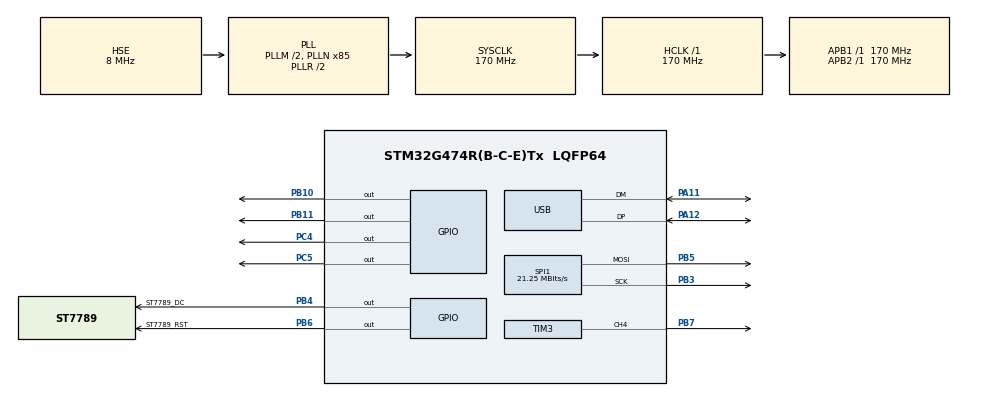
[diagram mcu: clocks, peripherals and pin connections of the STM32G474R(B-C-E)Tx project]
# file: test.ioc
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Dma.Request0=TIM3_CH4
Dma.TIM3_CH4.0.Direction=DMA_PERIPH_TO_MEMORY
Dma.TIM3_CH4.0.EventEnable=DISABLE
Dma.TIM3_CH4.0.Instance=DMA1_Channel1
Dma.TIM3_CH4.0.MemDataAlignment=DMA_MDATAALIGN_HALFWORD
Dma.TIM3_CH4.0.MemInc=DMA_MINC_ENABLE
Dma.TIM3_CH4.0.Mode=DMA_NORMAL
Dma.TIM3_CH4.0.PeriphDataAlignment=DMA_PDATAALIGN_HALFWORD
Dma.TIM3_CH4.0.PeriphInc=DMA_PINC_DISABLE
Dma.TIM3_CH4.0.Polarity=HAL_DMAMUX_REQ_GEN_RISING
Dma.TIM3_CH4.0.Priority=DMA_PRIORITY_LOW
Dma.TIM3_CH4.0.RequestNumber=1
Dma.TIM3_CH4.0.SignalID=NONE
Dma.TIM3_CH4.0.SyncEnable=DISABLE
Dma.TIM3_CH4.0.SyncPolarity=HAL_DMAMUX_SYNC_NO_EVENT
Dma.TIM3_CH4.0.SyncRequestNumber=1
Dma.TIM3_CH4.0.SyncSignalID=NONE
Mcu.Family=STM32G4
Mcu.Name=STM32G474R(B-C-E)Tx
Mcu.Package=LQFP64
NVIC.DMA1_Channel1_IRQn=true\:0\:0\:false\:false\:true\:false\:true\:true
NVIC.PriorityGroup=NVIC_PRIORITYGROUP_4
NVIC.USB_LP_IRQn=true\:0\:0\:false\:false\:true\:false\:true\:true
PA11.Mode=Device
PA11.Signal=USB_DM
PA12.Mode=Device
PA12.Signal=USB_DP
PA13.Mode=Serial_Wire
PA13.Signal=SYS_JTMS-SWDIO
PA14.Mode=Serial_Wire
PA14.Signal=SYS_JTCK-SWCLK
PB10.Signal=GPIO_Output
PB11.Signal=GPIO_Output
PB3.Mode=TX_Only_Simplex_Unidirect_Master
PB3.Signal=SPI1_SCK
PB4.GPIO_Label=ST7789_DC
PB4.Signal=GPIO_Output
PB5.Mode=TX_Only_Simplex_Unidirect_Master
PB5.Signal=SPI1_MOSI
PB6.GPIO_Label=ST7789_RST
PB6.Signal=GPIO_Output
PB7.GPIO_FM7=SYSCFG_FASTMODEPLUS_PB7
PB7.GPIO_ModeDefaultPP=GPIO_MODE_AF_OD
PB7.GPIO_Speed=GPIO_SPEED_FREQ_LOW
PB7.Signal=S_TIM3_CH4
PC14-OSC32_IN.Mode=LSE-External-Oscillator
PC14-OSC32_IN.Signal=RCC_OSC32_IN
PC15-OSC32_OUT.Mode=LSE-External-Oscillator
PC15-OSC32_OUT.Signal=RCC_OSC32_OUT
PC4.Signal=GPIO_Output
PC5.Signal=GPIO_Output
PF0-OSC_IN.Mode=HSE-External-Oscillator
PF0-OSC_IN.Signal=RCC_OSC_IN
PF1-OSC_OUT.Mode=HSE-External-Oscillator
PF1-OSC_OUT.Signal=RCC_OSC_OUT
ProjectManager.HeapSize=0x200
ProjectManager.StackSize=0x400
ProjectManager.TargetToolchain=STM32CubeIDE
RCC.ADC12Freq_Value=170000000
RCC.ADC345Freq_Value=170000000
RCC.AHBFreq_Value=170000000
RCC.APB1Freq_Value=170000000
RCC.APB1TimFreq_Value=170000000
RCC.APB2Freq_Value=170000000
RCC.APB2TimFreq_Value=170000000
RCC.CK48CLockSelection=RCC_USBCLKSOURCE_HSI48
RCC.CortexFreq_Value=170000000
RCC.EXTERNAL_CLOCK_VALUE=12288000
RCC.HCLKFreq_Value=170000000
RCC.HSE_VALUE=8000000
RCC.HSI48_VALUE=48000000
RCC.HSI_VALUE=16000000
RCC.PLLM=RCC_PLLM_DIV2
RCC.PLLN=85
RCC.PLLSourceVirtual=RCC_PLLSOURCE_HSE
RCC.SYSCLKFreq_VALUE=170000000
RCC.SYSCLKSource=RCC_SYSCLKSOURCE_PLLCLK
RCC.USBFreq_Value=48000000
RCC.VCOOutputFreq_Value=340000000
SH.S_TIM3_CH4.0=TIM3_CH4,PWM Generation4 CH4
SPI1.BaudRatePrescaler=SPI_BAUDRATEPRESCALER_8
SPI1.CalculateBaudRate=21.25 MBits/s
SPI1.Direction=SPI_DIRECTION_2LINES
SPI1.Mode=SPI_MODE_MASTER
SPI1.VirtualType=VM_MASTER
SYS.VoltageScaling=SYSCFG_VREFBUF_VOLTAGE_SCALE2
TIM3.AutoReloadPreload=TIM_AUTORELOAD_PRELOAD_ENABLE
TIM3.Channel-PWM\ Generation4\ CH4=TIM_CHANNEL_4
TIM3.PeriodNoDither=212
TIM3.Prescaler=0
USB_DEVICE.CLASS_NAME_FS=CDC
USB_DEVICE.VirtualMode=Cdc
USB_DEVICE.VirtualModeFS=Cdc_FS
VP_SYS_VS_DBSignals.Mode=DisableDeadBatterySignals
VP_TIM3_VS_ClockSourceINT.Mode=Internal
VP_USB_DEVICE_VS_USB_DEVICE_CDC_FS.Mode=CDC_FS
VREF+.Mode=InternalMode
VREF+.Signal=VREFBUF_OUT
board=custom

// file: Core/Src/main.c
/* USER CODE BEGIN Header */
/**
  ******************************************************************************
  * @file           : main.c
  * @brief          : Main program body
  ******************************************************************************
  * @attention
  *
  * Copyright (c) 2024 STMicroelectronics.
  * All rights reserved.
  *
  * This software is licensed under terms that can be found in the LICENSE file
  * in the root directory of this software component.
  * If no LICENSE file comes with this software, it is provided AS-IS.
  *
  ******************************************************************************
  */
/* USER CODE END Header */
#include "main.h"
#include "dma.h"
#include "spi.h"
#include "tim.h"
#include "usb_device.h"
#include "gpio.h"

/* USER CODE BEGIN Includes */
//#include "st7789.h"
//#include "fonts.h"

#include "libs.h"
//#include "ARGB.h"
#include "ws2812.h"

#include "usbd_cdc_if.h"

/* USER CODE END Includes */

/* USER CODE BEGIN PV */

extern USBD_HandleTypeDef hUsbDeviceFS;

/* USER CODE END PV */

void SystemClock_Config(void);

/* USER CODE BEGIN 0 */

uint8_t CDC_BUFFER[30] = {0};

/* USER CODE END 0 */

int main(void)
{

  /* MCU Configuration--------------------------------------------------------*/

  /* Reset of all peripherals, Initializes the Flash interface and the Systick. */
  HAL_Init();

  /* Configure the system clock */
  SystemClock_Config();

  /* Initialize all configured peripherals */
  MX_GPIO_Init();
  MX_DMA_Init();
  MX_SPI1_Init();
  MX_TIM3_Init();
  MX_USB_Device_Init();
  /* USER CODE BEGIN 2 */
  HAL_TIM_Base_Start(&htim3);
  HAL_TIM_PWM_Start(&htim3, TIM_CHANNEL_4);
//  ST7789_Init();
  /* USER CODE END 2 */

  /* Infinite loop */
  /* USER CODE BEGIN WHILE */
  while (1)
  {
//	  HAL_Delay(2000);
//	  ST7789_Test();
//	  HAL_Delay(1000);
//	  HAL_GPIO_WritePin(GPIOB, GPIO_PIN_10, 1);
//	  HAL_GPIO_WritePin(GPIOB, GPIO_PIN_11, 1);
//	  HAL_GPIO_WritePin(GPIOC, GPIO_PIN_4, 1);
//	  HAL_GPIO_WritePin(GPIOC, GPIO_PIN_5, 1);
//	    for (int i = 0; i < 2; i++)
//	    {
//	      ws2812_set_all(0xFFFFFF); // 纯白�???
//	      ws2812_gradient(200, 3);
//	      HAL_Delay(1000);
//
//	      ws2812_set_all(0x20B2AA); // 浅海洋绿
//	      ws2812_gradient(200, 3);
//	      HAL_Delay(1000);
//
//	      ws2812_set_all(0xFFD700); // 金色
//	      ws2812_gradient(200, 3);
//	      HAL_Delay(1000);
//
//	      // 更多颜色：https://www.w3schools.com/colors/colors_picker.asp
//	    }

      for (int period = 0; period < 100; period++) {
//          __HAL_TIM_SET_COMPARE(&htim3, TIM_CHANNEL_1, period);
          __HAL_TIM_SET_COMPARE(&htim3, TIM_CHANNEL_4, period);
          HAL_Delay(7);
      }
      // �???99逐渐减小�???0
      for (int period = 99; period >= 0; period--) {
//          __HAL_TIM_SET_COMPARE(&htim3, TIM_CHANNEL_1, period);
          __HAL_TIM_SET_COMPARE(&htim3, TIM_CHANNEL_4, period);
          HAL_Delay(7);
      }

//
//	  HAL_Delay(1000);
//	  HAL_GPIO_WritePin(GPIOB, GPIO_PIN_10, 0);
//	  HAL_GPIO_WritePin(GPIOB, GPIO_PIN_11, 0);
//	  HAL_GPIO_WritePin(GPIOC, GPIO_PIN_4, 0);
//	  HAL_GPIO_WritePin(GPIOC, GPIO_PIN_5, 0);
//	  sprintf(CDC_BUFFER,"1234\r\n");
//	  CDC_Transmit_FS(CDC_BUFFER, 20);

    /* USER CODE END WHILE */

  }
}

void SystemClock_Config(void)
{
  RCC_OscInitTypeDef RCC_OscInitStruct = {0};
  RCC_ClkInitTypeDef RCC_ClkInitStruct = {0};

  /** Configure the main internal regulator output voltage
  */
  HAL_PWREx_ControlVoltageScaling(PWR_REGULATOR_VOLTAGE_SCALE1_BOOST);

  /** Initializes the RCC Oscillators according to the specified parameters
  * in the RCC_OscInitTypeDef structure.
  */
  RCC_OscInitStruct.OscillatorType = RCC_OSCILLATORTYPE_HSI48|RCC_OSCILLATORTYPE_HSE;
  RCC_OscInitStruct.HSEState = RCC_HSE_ON;
  RCC_OscInitStruct.HSI48State = RCC_HSI48_ON;
  RCC_OscInitStruct.PLL.PLLState = RCC_PLL_ON;
  RCC_OscInitStruct.PLL.PLLSource = RCC_PLLSOURCE_HSE;
  RCC_OscInitStruct.PLL.PLLM = RCC_PLLM_DIV2;
  RCC_OscInitStruct.PLL.PLLN = 85;
  RCC_OscInitStruct.PLL.PLLP = RCC_PLLP_DIV2;
  RCC_OscInitStruct.PLL.PLLQ = RCC_PLLQ_DIV2;
  RCC_OscInitStruct.PLL.PLLR = RCC_PLLR_DIV2;
  if (HAL_RCC_OscConfig(&RCC_OscInitStruct) != HAL_OK)
  {
    Error_Handler();
  }

  /** Initializes the CPU, AHB and APB buses clocks
  */
  RCC_ClkInitStruct.ClockType = RCC_CLOCKTYPE_HCLK|RCC_CLOCKTYPE_SYSCLK
                              |RCC_CLOCKTYPE_PCLK1|RCC_CLOCKTYPE_PCLK2;
  RCC_ClkInitStruct.SYSCLKSource = RCC_SYSCLKSOURCE_PLLCLK;
  RCC_ClkInitStruct.AHBCLKDivider = RCC_SYSCLK_DIV1;
  RCC_ClkInitStruct.APB1CLKDivider = RCC_HCLK_DIV1;
  RCC_ClkInitStruct.APB2CLKDivider = RCC_HCLK_DIV1;

  if (HAL_RCC_ClockConfig(&RCC_ClkInitStruct, FLASH_LATENCY_4) != HAL_OK)
  {
    Error_Handler();
  }
}

void Error_Handler(void)
{
  __disable_irq();
  while (1)
  {
  }
}
